# STM32G484VET6 register map
File version: 1.0
Registers are 32-bit, access not given, reset 0x0 unless marked. A register's access mark holds for its fields unless they carry their own. Offsets are from the block's base; [hi:lo] are bit positions; {n}, {i} and the like mark numbered series.

## HRTIM1
Base 0x40016800
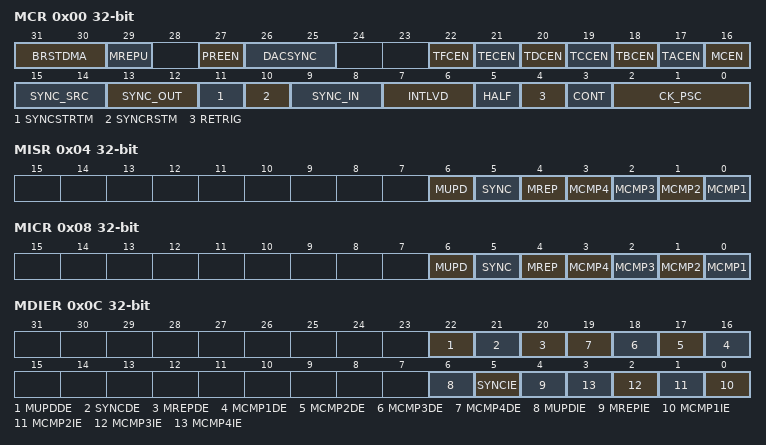
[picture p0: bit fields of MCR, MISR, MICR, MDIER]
0x00 MCR
  [31:30] BRSTDMA, [29] MREPU, [27] PREEN, [26:25] DACSYNC, [22] TFCEN, [21] TECEN, [20] TDCEN, [19] TCCEN, [18] TBCEN, [17] TACEN, [16] MCEN, [15:14] SYNC_SRC, [13:12] SYNC_OUT, [11] SYNCSTRTM, [10] SYNCRSTM, [9:8] SYNC_IN, [7:6] INTLVD, [5] HALF, [4] RETRIG, [3] CONT, [2:0] CK_PSC
0x04 MISR
  [6] MUPD, [5] SYNC, [4] MREP, [n-1] MCMP{n} (n=1..4)
0x08 MICR
  [6] MUPD, [5] SYNC, [4] MREP, [n-1] MCMP{n} (n=1..4)
0x0C MDIER
  [22] MUPDDE, [21] SYNCDE, [20] MREPDE, [n+15] MCMP{n}DE (n=1..4), [6] MUPDIE, [5] SYNCIE, [4] MREPIE, [n-1] MCMP{n}IE (n=1..4)
0x10 MCNTR
  [15:0] MCNTR
0x14 MPER
  [15:0] MPER
0x18 MREP
  [7:0] MREP
0x1C MCMP1R
  [15:0] MCMP1R
{0x1C+4i} MCMP{i}R (i=2..4)
  [15:0] MCMP{i}R
0x80 sTimerxRegs.0.TIMxCR
0x84 sTimerxRegs.0.TIMxISR
0x88 sTimerxRegs.0.TIMxICR
0x8C sTimerxRegs.0.TIMxDIER
0x90 sTimerxRegs.0.CNTxR
0x94 sTimerxRegs.0.PERxR
0x98 sTimerxRegs.0.REPxR
0x9C sTimerxRegs.0.CMP1xR
0xA0 sTimerxRegs.0.CMP1CxR
{0x9C+4i} sTimerxRegs.0.CMP{i}xR (i=2..4)
0xB0 sTimerxRegs.0.CPT1xR
0xB4 sTimerxRegs.0.CPT2xR
0xB8 sTimerxRegs.0.DTxR
0xBC sTimerxRegs.0.SETx1R
0xC0 sTimerxRegs.0.RSTx1R
0xC4 sTimerxRegs.0.SETx2R
0xC8 sTimerxRegs.0.RSTx2R
0xCC sTimerxRegs.0.EEFxR1
0xD0 sTimerxRegs.0.EEFxR2
0xD4 sTimerxRegs.0.RSTxR
0xD8 sTimerxRegs.0.CHPxR
0xDC sTimerxRegs.0.CPT1xCR
0xE0 sTimerxRegs.0.CPT2xCR
0xE4 sTimerxRegs.0.OUTxR
0xE8 sTimerxRegs.0.FLTxR
0xEC sTimerxRegs.0.TIMxCR2
0xF0 sTimerxRegs.0.EEFxR3
0x100 sTimerxRegs.1.TIMxCR
0x104 sTimerxRegs.1.TIMxISR
0x108 sTimerxRegs.1.TIMxICR
0x10C sTimerxRegs.1.TIMxDIER
0x110 sTimerxRegs.1.CNTxR
0x114 sTimerxRegs.1.PERxR
0x118 sTimerxRegs.1.REPxR
0x11C sTimerxRegs.1.CMP1xR
0x120 sTimerxRegs.1.CMP1CxR
{0x11C+4i} sTimerxRegs.1.CMP{i}xR (i=2..4)
0x130 sTimerxRegs.1.CPT1xR
0x134 sTimerxRegs.1.CPT2xR
0x138 sTimerxRegs.1.DTxR
0x13C sTimerxRegs.1.SETx1R
0x140 sTimerxRegs.1.RSTx1R
0x144 sTimerxRegs.1.SETx2R
0x148 sTimerxRegs.1.RSTx2R
0x14C sTimerxRegs.1.EEFxR1
0x150 sTimerxRegs.1.EEFxR2
0x154 sTimerxRegs.1.RSTxR
0x158 sTimerxRegs.1.CHPxR
0x15C sTimerxRegs.1.CPT1xCR
0x160 sTimerxRegs.1.CPT2xCR
0x164 sTimerxRegs.1.OUTxR
0x168 sTimerxRegs.1.FLTxR
0x16C sTimerxRegs.1.TIMxCR2
0x170 sTimerxRegs.1.EEFxR3
0x180 sTimerxRegs.2.TIMxCR
0x184 sTimerxRegs.2.TIMxISR
0x188 sTimerxRegs.2.TIMxICR
0x18C sTimerxRegs.2.TIMxDIER
0x190 sTimerxRegs.2.CNTxR
0x194 sTimerxRegs.2.PERxR
0x198 sTimerxRegs.2.REPxR
0x19C sTimerxRegs.2.CMP1xR
0x1A0 sTimerxRegs.2.CMP1CxR
{0x19C+4i} sTimerxRegs.2.CMP{i}xR (i=2..4)
0x1B0 sTimerxRegs.2.CPT1xR
0x1B4 sTimerxRegs.2.CPT2xR
0x1B8 sTimerxRegs.2.DTxR
0x1BC sTimerxRegs.2.SETx1R
0x1C0 sTimerxRegs.2.RSTx1R
0x1C4 sTimerxRegs.2.SETx2R
0x1C8 sTimerxRegs.2.RSTx2R
0x1CC sTimerxRegs.2.EEFxR1
0x1D0 sTimerxRegs.2.EEFxR2
0x1D4 sTimerxRegs.2.RSTxR
0x1D8 sTimerxRegs.2.CHPxR
0x1DC sTimerxRegs.2.CPT1xCR
0x1E0 sTimerxRegs.2.CPT2xCR
0x1E4 sTimerxRegs.2.OUTxR
0x1E8 sTimerxRegs.2.FLTxR
0x1EC sTimerxRegs.2.TIMxCR2
0x1F0 sTimerxRegs.2.EEFxR3
0x200 sTimerxRegs.3.TIMxCR
0x204 sTimerxRegs.3.TIMxISR
0x208 sTimerxRegs.3.TIMxICR
0x20C sTimerxRegs.3.TIMxDIER
0x210 sTimerxRegs.3.CNTxR
0x214 sTimerxRegs.3.PERxR
0x218 sTimerxRegs.3.REPxR
0x21C sTimerxRegs.3.CMP1xR
0x220 sTimerxRegs.3.CMP1CxR
{0x21C+4i} sTimerxRegs.3.CMP{i}xR (i=2..4)
0x230 sTimerxRegs.3.CPT1xR
0x234 sTimerxRegs.3.CPT2xR
0x238 sTimerxRegs.3.DTxR
0x23C sTimerxRegs.3.SETx1R
0x240 sTimerxRegs.3.RSTx1R
0x244 sTimerxRegs.3.SETx2R
0x248 sTimerxRegs.3.RSTx2R
0x24C sTimerxRegs.3.EEFxR1
0x250 sTimerxRegs.3.EEFxR2
0x254 sTimerxRegs.3.RSTxR
0x258 sTimerxRegs.3.CHPxR
0x25C sTimerxRegs.3.CPT1xCR
0x260 sTimerxRegs.3.CPT2xCR
0x264 sTimerxRegs.3.OUTxR
0x268 sTimerxRegs.3.FLTxR
0x26C sTimerxRegs.3.TIMxCR2
0x270 sTimerxRegs.3.EEFxR3
0x280 sTimerxRegs.4.TIMxCR
0x284 sTimerxRegs.4.TIMxISR
0x288 sTimerxRegs.4.TIMxICR
0x28C sTimerxRegs.4.TIMxDIER
0x290 sTimerxRegs.4.CNTxR
0x294 sTimerxRegs.4.PERxR
0x298 sTimerxRegs.4.REPxR
0x29C sTimerxRegs.4.CMP1xR
0x2A0 sTimerxRegs.4.CMP1CxR
{0x29C+4i} sTimerxRegs.4.CMP{i}xR (i=2..4)
0x2B0 sTimerxRegs.4.CPT1xR
0x2B4 sTimerxRegs.4.CPT2xR
0x2B8 sTimerxRegs.4.DTxR
0x2BC sTimerxRegs.4.SETx1R
0x2C0 sTimerxRegs.4.RSTx1R
0x2C4 sTimerxRegs.4.SETx2R
0x2C8 sTimerxRegs.4.RSTx2R
0x2CC sTimerxRegs.4.EEFxR1
0x2D0 sTimerxRegs.4.EEFxR2
0x2D4 sTimerxRegs.4.RSTxR
0x2D8 sTimerxRegs.4.CHPxR
0x2DC sTimerxRegs.4.CPT1xCR
0x2E0 sTimerxRegs.4.CPT2xCR
0x2E4 sTimerxRegs.4.OUTxR
0x2E8 sTimerxRegs.4.FLTxR
0x2EC sTimerxRegs.4.TIMxCR2
0x2F0 sTimerxRegs.4.EEFxR3
0x300 sTimerxRegs.5.TIMxCR
0x304 sTimerxRegs.5.TIMxISR
0x308 sTimerxRegs.5.TIMxICR
0x30C sTimerxRegs.5.TIMxDIER
0x310 sTimerxRegs.5.CNTxR
0x314 sTimerxRegs.5.PERxR
0x318 sTimerxRegs.5.REPxR
0x31C sTimerxRegs.5.CMP1xR
0x320 sTimerxRegs.5.CMP1CxR
{0x31C+4i} sTimerxRegs.5.CMP{i}xR (i=2..4)
0x330 sTimerxRegs.5.CPT1xR
0x334 sTimerxRegs.5.CPT2xR
0x338 sTimerxRegs.5.DTxR
0x33C sTimerxRegs.5.SETx1R
0x340 sTimerxRegs.5.RSTx1R
0x344 sTimerxRegs.5.SETx2R
0x348 sTimerxRegs.5.RSTx2R
0x34C sTimerxRegs.5.EEFxR1
0x350 sTimerxRegs.5.EEFxR2
0x354 sTimerxRegs.5.RSTxR
0x358 sTimerxRegs.5.CHPxR
0x35C sTimerxRegs.5.CPT1xCR
0x360 sTimerxRegs.5.CPT2xCR
0x364 sTimerxRegs.5.OUTxR
0x368 sTimerxRegs.5.FLTxR
0x36C sTimerxRegs.5.TIMxCR2
0x370 sTimerxRegs.5.EEFxR3
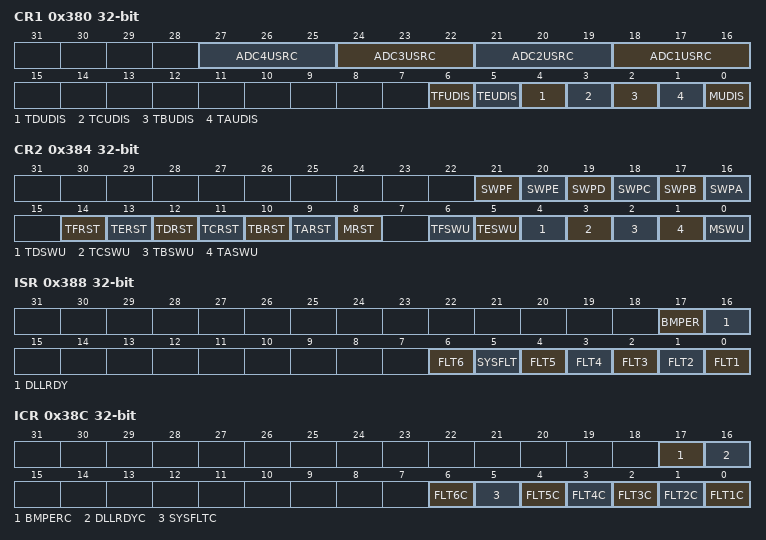
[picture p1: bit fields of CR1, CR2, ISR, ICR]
0x380 CR1
  [3n+15:3n+13] ADC{n}USRC (n=1..4), [6] TFUDIS, [5] TEUDIS, [4] TDUDIS, [3] TCUDIS, [2] TBUDIS, [1] TAUDIS, [0] MUDIS
0x384 CR2
  [21] SWPF, [20] SWPE, [19] SWPD, [18] SWPC, [17] SWPB, [16] SWPA, [14] TFRST, [13] TERST, [12] TDRST, [11] TCRST, [10] TBRST, [9] TARST, [8] MRST, [6] TFSWU, [5] TESWU, [4] TDSWU, [3] TCSWU, [2] TBSWU, [1] TASWU, [0] MSWU
0x388 ISR
  [17] BMPER, [16] DLLRDY, [6] FLT6, [5] SYSFLT, [n-1] FLT{n} (n=1..5)
0x38C ICR
  [17] BMPERC, [16] DLLRDYC, [6] FLT6C, [5] SYSFLTC, [n-1] FLT{n}C (n=1..5)
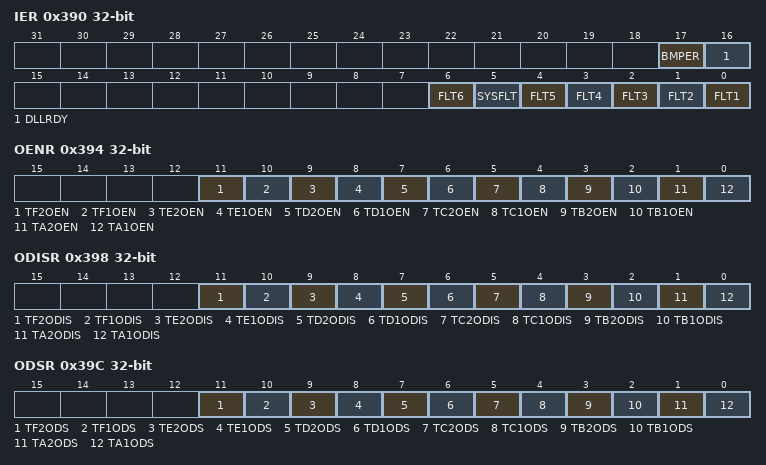
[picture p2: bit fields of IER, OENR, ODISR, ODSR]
0x390 IER
  [17] BMPER, [16] DLLRDY, [6] FLT6, [5] SYSFLT, [n-1] FLT{n} (n=1..5)
0x394 OENR
  [11] TF2OEN, [10] TF1OEN, [9] TE2OEN, [8] TE1OEN, [7] TD2OEN, [6] TD1OEN, [5] TC2OEN, [4] TC1OEN, [3] TB2OEN, [2] TB1OEN, [1] TA2OEN, [0] TA1OEN
0x398 ODISR
  [11] TF2ODIS, [10] TF1ODIS, [9] TE2ODIS, [8] TE1ODIS, [7] TD2ODIS, [6] TD1ODIS, [5] TC2ODIS, [4] TC1ODIS, [3] TB2ODIS, [2] TB1ODIS, [1] TA2ODIS, [0] TA1ODIS
0x39C ODSR
  [11] TF2ODS, [10] TF1ODS, [9] TE2ODS, [8] TE1ODS, [7] TD2ODS, [6] TD1ODS, [5] TC2ODS, [4] TC1ODS, [3] TB2ODS, [2] TB1ODS, [1] TA2ODS, [0] TA1ODS
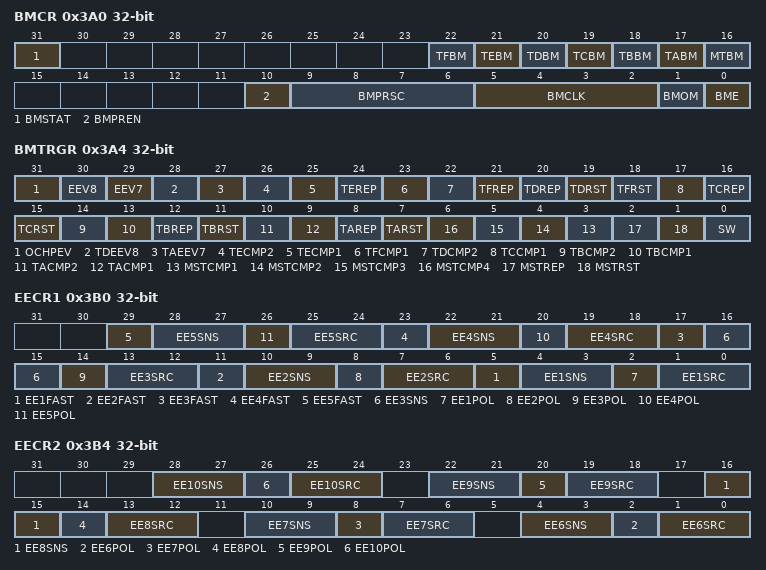
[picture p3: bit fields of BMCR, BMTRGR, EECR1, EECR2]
0x3A0 BMCR
  [31] BMSTAT, [22] TFBM, [21] TEBM, [20] TDBM, [19] TCBM, [18] TBBM, [17] TABM, [16] MTBM, [10] BMPREN, [9:6] BMPRSC, [5:2] BMCLK, [1] BMOM, [0] BME
0x3A4 BMTRGR
  [31] OCHPEV, [30] EEV8, [29] EEV7, [28] TDEEV8, [27] TAEEV7, [26] TECMP2, [25] TECMP1, [24] TEREP, [23] TFCMP1, [22] TDCMP2, [21] TFREP, [20] TDREP, [19] TDRST, [18] TFRST, [17] TCCMP1, [16] TCREP, [15] TCRST, [14] TBCMP2, [13] TBCMP1, [12] TBREP, [11] TBRST, [10] TACMP2, [9] TACMP1, [8] TAREP, [7] TARST, [n+2] MSTCMP{n} (n=1..4), [2] MSTREP, [1] MSTRST, [0] SW
0x3A8 BMCMPR
  [15:0] BMCMPR
0x3AC BMPER
  [15:0] BMPER
0x3B0 EECR1
  [6n-1] EE{n}FAST (n=1..5), [6n-2:6n-3] EE{n}SNS (n=1..5), [6n-4] EE{n}POL (n=1..5), [6n-5:6n-6] EE{n}SRC (n=1..5)
0x3B4 EECR2
  [6n-32:6n-33] EE{n}SNS (n=6..10), [6n-34] EE{n}POL (n=6..10), [6n-35:6n-36] EE{n}SRC (n=6..10)
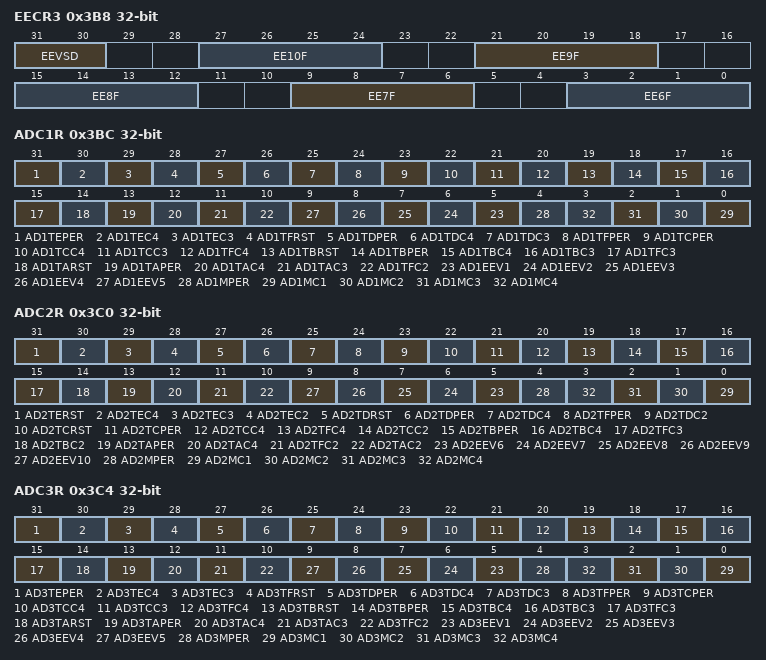
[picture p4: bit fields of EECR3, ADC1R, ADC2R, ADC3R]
0x3B8 EECR3
  [31:30] EEVSD, [6n-33:6n-36] EE{n}F (n=6..10)
0x3BC ADC1R
  [31] AD1TEPER, [30] AD1TEC4, [29] AD1TEC3, [28] AD1TFRST, [27] AD1TDPER, [26] AD1TDC4, [25] AD1TDC3, [24] AD1TFPER, [23] AD1TCPER, [22] AD1TCC4, [21] AD1TCC3, [20] AD1TFC4, [19] AD1TBRST, [18] AD1TBPER, [17] AD1TBC4, [16] AD1TBC3, [15] AD1TFC3, [14] AD1TARST, [13] AD1TAPER, [12] AD1TAC4, [11] AD1TAC3, [10] AD1TFC2, [n+4] AD1EEV{n} (n=1..5), [4] AD1MPER, [n-1] AD1MC{n} (n=1..4)
0x3C0 ADC2R
  [31] AD2TERST, [30] AD2TEC4, [29] AD2TEC3, [28] AD2TEC2, [27] AD2TDRST, [26] AD2TDPER, [25] AD2TDC4, [24] AD2TFPER, [23] AD2TDC2, [22] AD2TCRST, [21] AD2TCPER, [20] AD2TCC4, [19] AD2TFC4, [18] AD2TCC2, [17] AD2TBPER, [16] AD2TBC4, [15] AD2TFC3, [14] AD2TBC2, [13] AD2TAPER, [12] AD2TAC4, [11] AD2TFC2, [10] AD2TAC2, [n-1] AD2EEV{n} (n=6..10), [4] AD2MPER, [n-1] AD2MC{n} (n=1..4)
0x3C4 ADC3R
  [31] AD3TEPER, [30] AD3TEC4, [29] AD3TEC3, [28] AD3TFRST, [27] AD3TDPER, [26] AD3TDC4, [25] AD3TDC3, [24] AD3TFPER, [23] AD3TCPER, [22] AD3TCC4, [21] AD3TCC3, [20] AD3TFC4, [19] AD3TBRST, [18] AD3TBPER, [17] AD3TBC4, [16] AD3TBC3, [15] AD3TFC3, [14] AD3TARST, [13] AD3TAPER, [12] AD3TAC4, [11] AD3TAC3, [10] AD3TFC2, [n+4] AD3EEV{n} (n=1..5), [4] AD3MPER, [n-1] AD3MC{n} (n=1..4)
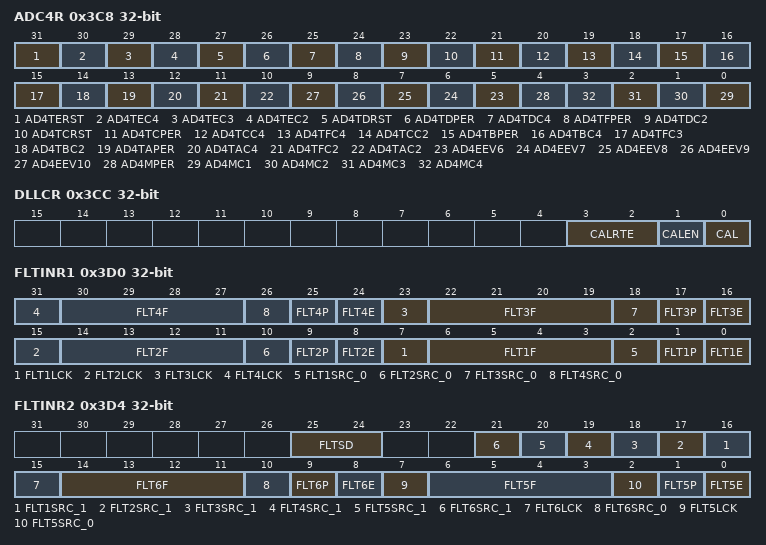
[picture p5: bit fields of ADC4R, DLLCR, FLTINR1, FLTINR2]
0x3C8 ADC4R
  [31] AD4TERST, [30] AD4TEC4, [29] AD4TEC3, [28] AD4TEC2, [27] AD4TDRST, [26] AD4TDPER, [25] AD4TDC4, [24] AD4TFPER, [23] AD4TDC2, [22] AD4TCRST, [21] AD4TCPER, [20] AD4TCC4, [19] AD4TFC4, [18] AD4TCC2, [17] AD4TBPER, [16] AD4TBC4, [15] AD4TFC3, [14] AD4TBC2, [13] AD4TAPER, [12] AD4TAC4, [11] AD4TFC2, [10] AD4TAC2, [n-1] AD4EEV{n} (n=6..10), [4] AD4MPER, [n-1] AD4MC{n} (n=1..4)
0x3CC DLLCR
  [3:2] CALRTE, [1] CALEN, [0] CAL
0x3D0 FLTINR1
  [8n-1] FLT{n}LCK (n=1..4), [8n-2:8n-5] FLT{n}F (n=1..4), [8n-6] FLT{n}SRC_0 (n=1..4), [8n-7] FLT{n}P (n=1..4), [8n-8] FLT{n}E (n=1..4)
0x3D4 FLTINR2
  [25:24] FLTSD, [n+15] FLT{n}SRC_1 (n=1..6), [15] FLT6LCK, [14:11] FLT6F, [10] FLT6SRC_0, [9] FLT6P, [8] FLT6E, [7] FLT5LCK, [6:3] FLT5F, [2] FLT5SRC_0, [1] FLT5P, [0] FLT5E
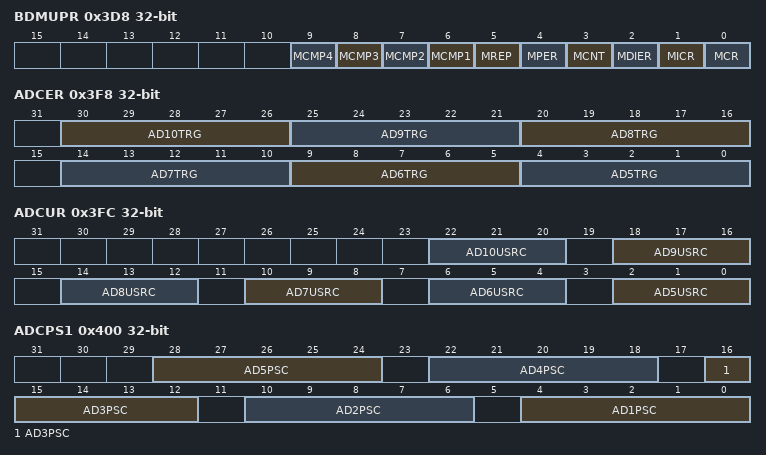
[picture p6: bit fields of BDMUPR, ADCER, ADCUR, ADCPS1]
0x3D8 BDMUPR
  [n+5] MCMP{n} (n=1..4), [5] MREP, [4] MPER, [3] MCNT, [2] MDIER, [1] MICR, [0] MCR
0x3DC BDTAUPR
0x3E0 BDTBUPR
0x3E4 BDTCUPR
0x3E8 BDTDUPR
0x3EC BDTEUPR
0x3F0 BDMADR
0x3F4 BDTFUPR
0x3F8 ADCER
  [30:26] AD10TRG, [25:21] AD9TRG, [20:16] AD8TRG, [14:10] AD7TRG, [9:5] AD6TRG, [4:0] AD5TRG
0x3FC ADCUR
  [4n-18:4n-20] AD{n}USRC (n=5..10)
0x400 ADCPS1
  [6n-2:6n-6] AD{n}PSC (n=1..5)
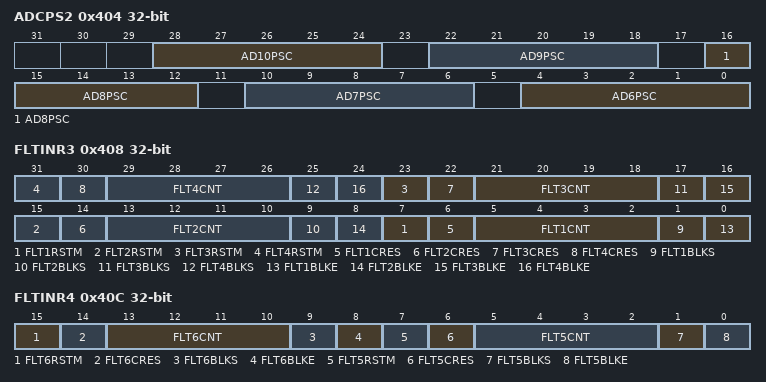
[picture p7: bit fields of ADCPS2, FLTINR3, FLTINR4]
0x404 ADCPS2
  [6n-32:6n-36] AD{n}PSC (n=6..10)
0x408 FLTINR3
  [8n-1] FLT{n}RSTM (n=1..4), [8n-2] FLT{n}CRES (n=1..4), [8n-3:8n-6] FLT{n}CNT (n=1..4), [8n-7] FLT{n}BLKS (n=1..4), [8n-8] FLT{n}BLKE (n=1..4)
0x40C FLTINR4
  [15] FLT6RSTM, [14] FLT6CRES, [13:10] FLT6CNT, [9] FLT6BLKS, [8] FLT6BLKE, [7] FLT5RSTM, [6] FLT5CRES, [5:2] FLT5CNT, [1] FLT5BLKS, [0] FLT5BLKE
